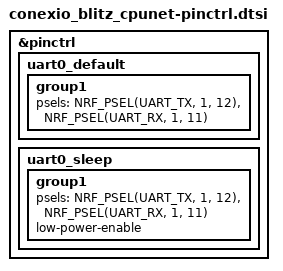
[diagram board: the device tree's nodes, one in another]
/*
 * Copyright (c) 2024 Conexio Technologies, Inc
 * Copyright (c) 2022 Nordic Semiconductor
 * SPDX-License-Identifier: Apache-2.0
 */

&pinctrl {
	uart0_default: uart0_default {
		group1 {
			psels = <NRF_PSEL(UART_TX, 1, 12)>,
				<NRF_PSEL(UART_RX, 1, 11)>;
		};
	};

	uart0_sleep: uart0_sleep {
		group1 {
			psels = <NRF_PSEL(UART_TX, 1, 12)>,
				<NRF_PSEL(UART_RX, 1, 11)>;
			low-power-enable;
		};
	};

};
